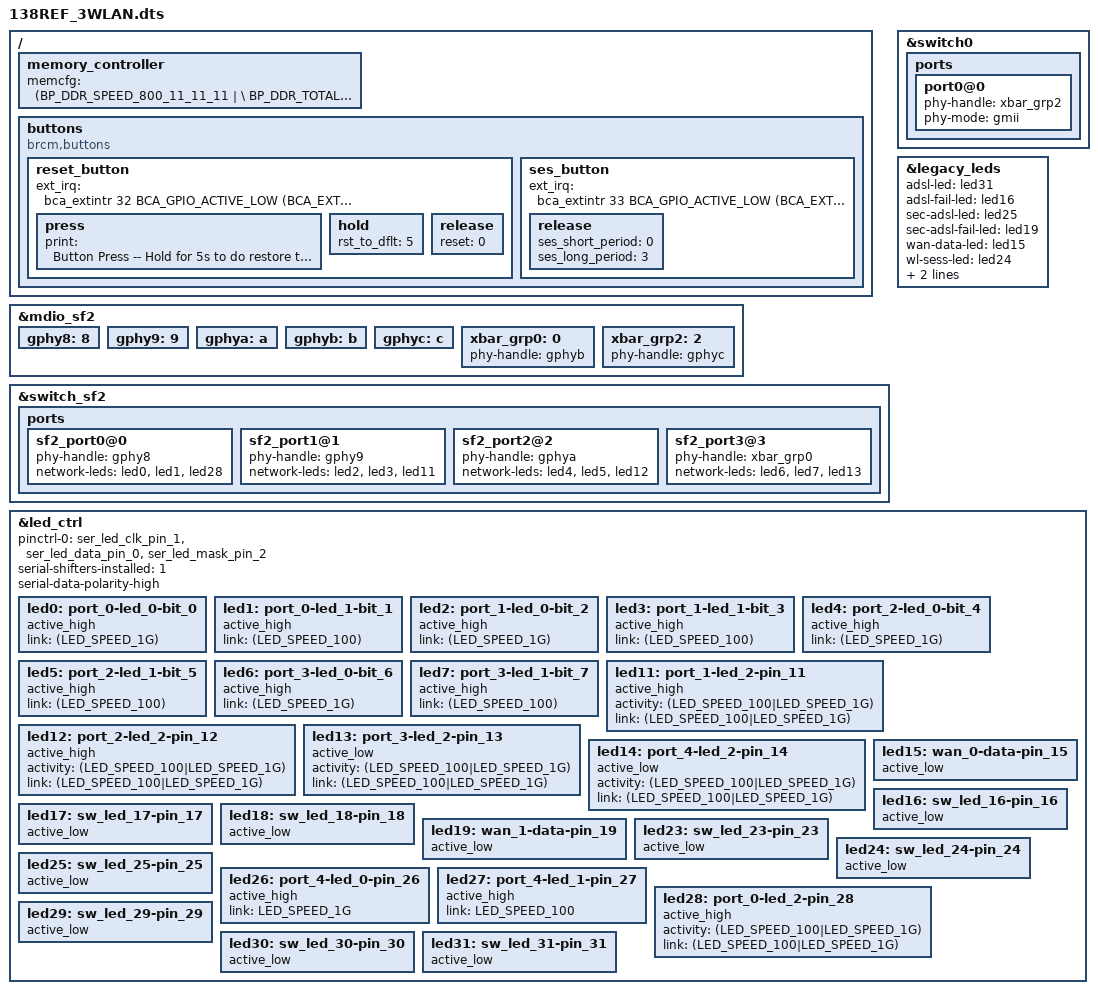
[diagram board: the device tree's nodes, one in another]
#include "63138.dtsi"

/ {
	memory_controller {
		memcfg = <(BP_DDR_SPEED_800_11_11_11   | \
			BP_DDR_TOTAL_SIZE_512MB  | \
			BP_DDR_DEVICE_WIDTH_16)>;
	};

	buttons {
		compatible = "brcm,buttons";
		reset_button {
			ext_irq = <&bca_extintr 32 BCA_GPIO_ACTIVE_LOW (BCA_EXTINTR_TYPE_LOW_LEVEL | BCA_EXTINTR_TYPE_SENSE_LEVEL)>;
			press {
				print = "Button Press -- Hold for 5s to do restore to default";
			};
			hold {
				rst_to_dflt = <5>;
			};
			release {
				reset = <0>;
			};	
		};
		ses_button {
			ext_irq = <&bca_extintr 33 BCA_GPIO_ACTIVE_LOW (BCA_EXTINTR_TYPE_LOW_LEVEL | BCA_EXTINTR_TYPE_SENSE_LEVEL)>;
			release {
				ses_short_period = <0>;
				ses_long_period = <3>;
			};
		};
	};
};


&mdio_sf2 {
	/* PHYs directly connected to SF2 */
	gphy8:8 {
		status = "okay";
	};
	gphy9:9 {
		status = "okay";
	};
	gphya:a {
		status = "okay";
	};

	/* PHYs connected to crossbar */
	gphyb:b {
		status = "okay";
	};
	gphyc:c {
		status = "okay";
	};

	/* Crossbar groups */
	xbar_grp0:0 {
		phy-handle = <&gphyb>;
		status = "okay";
	};
	xbar_grp2:2 {
		phy-handle = <&gphyc>;
		status = "okay";
	};
};

&switch_sf2 {
	ports {
		/* ports connect directly */
		sf2_port0@0 {
			phy-handle = <&gphy8>;
			network-leds = <&led0 &led1 &led28>;
			status = "okay";
		};

		sf2_port1@1 {
			phy-handle = <&gphy9>;
			network-leds = <&led2 &led3 &led11>;
			status = "okay";
		};

		sf2_port2@2 {
			phy-handle = <&gphya>;
			network-leds = <&led4 &led5 &led12>;
			status = "okay";
		};

		/* ports connected to crossbar */
		sf2_port3@3 {
			phy-handle = <&xbar_grp0>;
			network-leds = <&led6 &led7 &led13>;
			status = "okay";
		};
	};
};

&switch0 {
	ports {
		
		port0@0 {
			phy-handle = <&xbar_grp2>;
			phy-mode = "gmii";
			status = "okay";
		};
	};
};

&legacy_leds {
	adsl-led = <&led31>;
	adsl-fail-led = <&led16>;
	sec-adsl-led = <&led25>;
	sec-adsl-fail-led = <&led19>;
	wan-data-led = <&led15>;
	wl-sess-led = <&led24>;
	voip1-ok-led = <&led17>;
	voip2-ok-led = <&led18>;
};

&led_ctrl {
    pinctrl-names = "default";
    pinctrl-0 = <&ser_led_clk_pin_1 &ser_led_data_pin_0 &ser_led_mask_pin_2>;
    serial-shifters-installed = <1>;
    serial-data-polarity-high;

    led0: port_0-led_0-bit_0 {
        active_high;
        link = <(LED_SPEED_1G)>;
        status = "okay";
    };
    led1: port_0-led_1-bit_1 {
        active_high;
        link = <(LED_SPEED_100)>;
        status = "okay";
    };
    led2: port_1-led_0-bit_2 {
        active_high;
        link = <(LED_SPEED_1G)>;
        status = "okay";
    };
    led3: port_1-led_1-bit_3 {
        active_high;
        link = <(LED_SPEED_100)>;
        status = "okay";
    };
    led4: port_2-led_0-bit_4 {
        active_high;
        link = <(LED_SPEED_1G)>;
        status = "okay";
    };
    led5: port_2-led_1-bit_5 {
        active_high;
        link = <(LED_SPEED_100)>;
        status = "okay";
    };
    led6: port_3-led_0-bit_6 {
        active_high;
        link = <(LED_SPEED_1G)>;
        status = "okay";
    };
    led7: port_3-led_1-bit_7 {
        active_high;
        link = <(LED_SPEED_100)>;
        status = "okay";
    };
    led11: port_1-led_2-pin_11 {
        active_high;
        activity = <(LED_SPEED_100|LED_SPEED_1G)>;
        link = <(LED_SPEED_100|LED_SPEED_1G)>;
        status = "okay";
    };
    led12: port_2-led_2-pin_12 {
        active_high;
        activity = <(LED_SPEED_100|LED_SPEED_1G)>;
        link = <(LED_SPEED_100|LED_SPEED_1G)>;
        status = "okay";
    };
    led13: port_3-led_2-pin_13 {
        active_low;
        activity = <(LED_SPEED_100|LED_SPEED_1G)>;
        link = <(LED_SPEED_100|LED_SPEED_1G)>;
        status = "okay";
    };    
    led14: port_4-led_2-pin_14 {
        active_low;
        activity = <(LED_SPEED_100|LED_SPEED_1G)>;
        link = <(LED_SPEED_100|LED_SPEED_1G)>;
        status = "okay";
    };
    led15: wan_0-data-pin_15 {
        active_low;
        status = "okay";
    };
    led16: sw_led_16-pin_16 {
        active_low;
        status = "okay";
    };
    led17: sw_led_17-pin_17 {
        active_low;
        status = "okay";
    };
    led18: sw_led_18-pin_18 {
        active_low;
        status = "okay";
    };
    led19: wan_1-data-pin_19 {
        active_low;
        status = "okay";
    };
    led23: sw_led_23-pin_23 {
        active_low;
        status = "okay";
    };
    led24: sw_led_24-pin_24 {
        active_low;
        status = "okay";
    };
	led25: sw_led_25-pin_25 {
        active_low;
        status = "okay";
    };
    led26: port_4-led_0-pin_26 {
        active_high;
        link = <LED_SPEED_1G>;
        status = "okay";
    };
	led27: port_4-led_1-pin_27 {
        active_high;
        link = <LED_SPEED_100>;
        status = "okay";
    };
    led28: port_0-led_2-pin_28 {
        active_high;
        activity = <(LED_SPEED_100|LED_SPEED_1G)>;
        link = <(LED_SPEED_100|LED_SPEED_1G)>;
        status = "okay";
    };
    led29: sw_led_29-pin_29 {
        active_low;
        status = "okay";
    };
    led30: sw_led_30-pin_30 {
        active_low;
        status = "okay";
    };
    led31: sw_led_31-pin_31 {
        active_low;
        status = "okay";
    };
};
